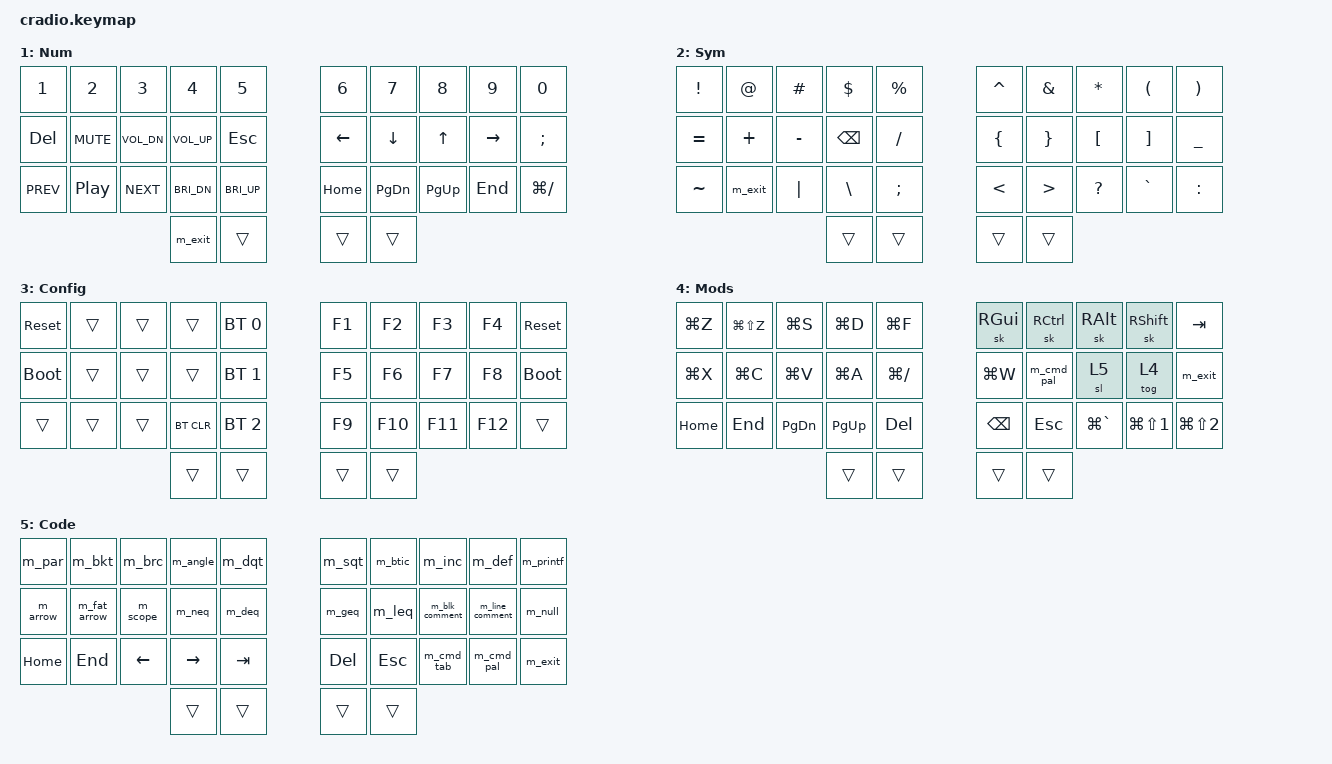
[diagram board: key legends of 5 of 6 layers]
// Copyright (c) 2022 The ZMK Contributors
// SPDX-License-Identifier: MIT

// ─── C / General Coding Optimised Keymap ─────────────────────────────────────
//
// Key ideas:
//  • Bracket-pair macros — type the pair, cursor lands INSIDE: () {} [] "" '' ``
//    reached via combos (UI OP IO) and Code layer — NOT on Sym row 0
//  • EXIT→→ macro           — double RIGHT, hops past closing bracket/quote
//                             Num left thumb (30), Sym row2 (21), Code/Mod layers
//  • Key Repeat (pos 30)   — repeats last key; ideal for arrows, chars, etc.
//  • Standard symbol row    — Sym TOP ROW mirrors shift+1–0 exactly:
//                             !  @  #  $  %  ^  &  *  (  )
//  • Complete symbol set    — every symbol reachable on Sym without shift:
//                             Row 1: =  +  -  BSPC  /  {  }  [  ]  _
//                             Row 2: ~  EXIT  |  \  ;  <  >  ?  `  :
//  • C-specific macros      — -> => :: /* */ // #include <> #define printf("") NULL
//  • Comparison macros      — != == >= <=  on Code layer + combos
//  • Cmd+Tab macro          — app switcher on Sym right outer thumb + combo RT
//  • Combos on natural rolls — SD=Esc  JK=Tab  JKL=Mods  AS=Code  DF=:
//                             QW=⌘Z  WE=⌘⇧Z  ZX=⌘S  RT=⌘Tab  ,.=;
//                             UI=()  IO={}  OP=[]  HJ===  NM=!=  XC=""
//                             VB=/**/
//  • All shortcuts use Cmd (⌘) not Ctrl — macOS native
//
// Symbols layer at a glance:
//   Row 0  !  @  #  $  %    ^  &  *  (  )    ← standard shift+number row
//   Row 1  =  +  -  BSPC /  {  }  [  ]  _   ← arithmetic + brackets + BSPC
//   Row 2  ~  EXIT |  \  ;  <  >  ?  `  :   ← bitwise / misc + EXIT→→
//   Thumb  —  [held]         —     ⌘Tab
//
// Layer index:
//   0  Base     (QWERTY + HRM)
//   1  Num      (right thumb hold)
//   2  Sym      (left thumb hold)
//   3  Config   (tri-layer: 1 + 2)
//   4  Mods     (JKL combo toggle)
//   5  Code     (sticky / one-shot, access via AS combo or Mods layer)

#include <behaviors.dtsi>
#include <dt-bindings/zmk/keys.h>
#include <dt-bindings/zmk/bt.h>

// ─── Home row mod helpers ─────────────────────────────────────────────────────
// Left:  A=LSHFT  S=LALT  D=LCTRL  F=LGUI
// Right: J=RGUI   K=RCTRL L=RALT   '=RSHFT
//
// FIX: Both HRML(k1) and HRMR(k4) now use &ht so the outer home-row keys
//      (A=LSHFT and '=RSHFT) actually fire their hold behaviour.
#define HRML(k1,k2,k3,k4) &ht LSHFT k1  &ht LALT k2  &ht LCTRL k3  &ht LGUI k4
#define HRMR(k1,k2,k3,k4) &ht RGUI k1   &ht RCTRL k2 &ht RALT k3   &ht RSHFT k4

// ─── Hold-tap tuning ──────────────────────────────────────────────────────────
&lt {
    flavor = "tap-preferred";
    tapping-term-ms = <250>;
    quick-tap-ms = <180>;
    require-prior-idle-ms = <100>;
};

&sk {
    release-after-ms = <2000>;
    quick-release;
};

&sl {
    release-after-ms = <2000>;
};

// ─── Root node ────────────────────────────────────────────────────────────────
/ {

    // ── Behaviors ─────────────────────────────────────────────────────────────

    behaviors {

        ht: hold_tap {
            compatible = "zmk,behavior-hold-tap";
            #binding-cells = <2>;
            flavor = "tap-preferred";
            tapping-term-ms = <280>;
            quick-tap-ms = <180>;
            require-prior-idle-ms = <125>;
            bindings = <&kp>, <&kp>;
        };

        ccaps_word: caps_word {
            compatible = "zmk,behavior-caps-word";
            #binding-cells = <0>;
            continue-list = <UNDERSCORE MINUS BACKSPACE>;
        };

        rpt: key_repeat {
            compatible = "zmk,behavior-key-repeat";
            #binding-cells = <0>;
            usage-pages = <HID_USAGE_KEY HID_USAGE_CONSUMER>;
        };

    };

    // ── Macros ────────────────────────────────────────────────────────────────
    //
    // Bracket-pair macros type open+close then move LEFT → cursor is inside.
    // They live on combos (Base layer) and on Code layer (L5).
    // The Sym layer (L2) exposes raw individual symbols only.
    //
    // tap-ms / wait-ms = 15 ms keeps HID events ordered over BLE.

    macros {

        // ── Bracket pairs (cursor inside after) ───────────────────────────────

        m_par: macro_parens {
            compatible = "zmk,behavior-macro";
            #binding-cells = <0>;
            wait-ms = <15>; tap-ms = <15>;
            bindings = <&kp LPAR &kp RPAR &kp LEFT>;
        };

        m_bkt: macro_brackets {
            compatible = "zmk,behavior-macro";
            #binding-cells = <0>;
            wait-ms = <15>; tap-ms = <15>;
            bindings = <&kp LBKT &kp RBKT &kp LEFT>;
        };

        m_brc: macro_braces {
            compatible = "zmk,behavior-macro";
            #binding-cells = <0>;
            wait-ms = <15>; tap-ms = <15>;
            bindings = <&kp LBRC &kp RBRC &kp LEFT>;
        };

        m_dqt: macro_double_quote {
            compatible = "zmk,behavior-macro";
            #binding-cells = <0>;
            wait-ms = <15>; tap-ms = <15>;
            bindings = <&kp DQT &kp DQT &kp LEFT>;
        };

        m_sqt: macro_single_quote {
            compatible = "zmk,behavior-macro";
            #binding-cells = <0>;
            wait-ms = <15>; tap-ms = <15>;
            bindings = <&kp SQT &kp SQT &kp LEFT>;
        };

        m_btic: macro_backtick {
            compatible = "zmk,behavior-macro";
            #binding-cells = <0>;
            wait-ms = <15>; tap-ms = <15>;
            bindings = <&kp GRAVE &kp GRAVE &kp LEFT>;
        };

        m_angle: macro_angle_brackets {
            compatible = "zmk,behavior-macro";
            #binding-cells = <0>;
            wait-ms = <15>; tap-ms = <15>;
            bindings = <&kp LT &kp GT &kp LEFT>;
        };

        // ── Exit bracket ───────────────────────────────────────────────────────
        // Two RIGHT presses: covers manually typed AND editor-autoclosed brackets.

        m_exit: macro_exit_bracket {
            compatible = "zmk,behavior-macro";
            #binding-cells = <0>;
            wait-ms = <15>; tap-ms = <15>;
            bindings = <&kp RIGHT &kp RIGHT>;
        };

        // ── C / multi-language snippets ────────────────────────────────────────

        m_arrow: macro_arrow {          // ->
            compatible = "zmk,behavior-macro";
            #binding-cells = <0>;
            wait-ms = <15>; tap-ms = <15>;
            bindings = <&kp MINUS &kp GT>;
        };

        m_fat_arrow: macro_fat_arrow {  // =>
            compatible = "zmk,behavior-macro";
            #binding-cells = <0>;
            wait-ms = <15>; tap-ms = <15>;
            bindings = <&kp EQUAL &kp GT>;
        };

        m_scope: macro_scope {          // ::
            compatible = "zmk,behavior-macro";
            #binding-cells = <0>;
            wait-ms = <15>; tap-ms = <15>;
            bindings = <&kp COLON &kp COLON>;
        };

        m_blk_comment: macro_block_comment {   // /*  */  cursor between spaces
            compatible = "zmk,behavior-macro";
            #binding-cells = <0>;
            wait-ms = <15>; tap-ms = <15>;
            bindings =
                <&kp FSLH &kp ASTRK &kp SPACE &kp SPACE &kp ASTRK &kp FSLH>,
                <&kp LEFT &kp LEFT &kp LEFT>;
        };

        m_line_comment: macro_line_comment {   // // (with trailing space)
            compatible = "zmk,behavior-macro";
            #binding-cells = <0>;
            wait-ms = <15>; tap-ms = <15>;
            bindings = <&kp FSLH &kp FSLH &kp SPACE>;
        };

        m_neq: macro_not_equal {        // !=
            compatible = "zmk,behavior-macro";
            #binding-cells = <0>;
            wait-ms = <15>; tap-ms = <15>;
            bindings = <&kp EXCL &kp EQUAL>;
        };

        m_deq: macro_double_equal {     // ==
            compatible = "zmk,behavior-macro";
            #binding-cells = <0>;
            wait-ms = <15>; tap-ms = <15>;
            bindings = <&kp EQUAL &kp EQUAL>;
        };

        m_geq: macro_geq {              // >=
            compatible = "zmk,behavior-macro";
            #binding-cells = <0>;
            wait-ms = <15>; tap-ms = <15>;
            bindings = <&kp GT &kp EQUAL>;
        };

        m_leq: macro_leq {              // <=
            compatible = "zmk,behavior-macro";
            #binding-cells = <0>;
            wait-ms = <15>; tap-ms = <15>;
            bindings = <&kp LT &kp EQUAL>;
        };

        // FIX: m_inc — replaced fragile &macro_press/tap/release LSHFT+N3 pattern
        //      with direct &kp HASH (defined in zmk/keys.h). Same fix for m_def.
        m_inc: macro_include {          // #include <|>
            compatible = "zmk,behavior-macro";
            #binding-cells = <0>;
            wait-ms = <15>; tap-ms = <15>;
            bindings =
                <&kp HASH>,
                <&kp I &kp N &kp C &kp L &kp U &kp D &kp E &kp SPACE>,
                <&kp LT &kp GT &kp LEFT>;
        };

        m_def: macro_define {           // #define (trailing space)
            compatible = "zmk,behavior-macro";
            #binding-cells = <0>;
            wait-ms = <15>; tap-ms = <15>;
            bindings =
                <&kp HASH>,
                <&kp D &kp E &kp F &kp I &kp N &kp E &kp SPACE>;
        };

        m_printf: macro_printf {        // printf("|")
            compatible = "zmk,behavior-macro";
            #binding-cells = <0>;
            wait-ms = <15>; tap-ms = <15>;
            bindings =
                <&kp P &kp R &kp I &kp N &kp T &kp F>,
                <&kp LPAR &kp DQT &kp DQT &kp RPAR &kp SEMI>,
                <&kp LEFT &kp LEFT &kp LEFT>;
        };

        // FIX: m_null — replaced broken &macro_press/tap/release pattern with
        //      individual &kp LS(...) calls, which correctly hold shift per key.
        m_null: macro_null {            // NULL
            compatible = "zmk,behavior-macro";
            #binding-cells = <0>;
            wait-ms = <15>; tap-ms = <15>;
            bindings = <&kp LS(N) &kp LS(U) &kp LS(L) &kp LS(L)>;
        };

        // ── OS macros ─────────────────────────────────────────────────────────

        m_cmd_tab: macro_cmd_tab {      // ⌘Tab — app switcher
            compatible = "zmk,behavior-macro";
            #binding-cells = <0>;
            wait-ms = <15>; tap-ms = <15>;
            bindings = <&kp LG(TAB)>;
        };

        m_cmd_pal: macro_cmd_palette {  // ⌘⇧P — command palette
            compatible = "zmk,behavior-macro";
            #binding-cells = <0>;
            wait-ms = <15>; tap-ms = <15>;
            bindings = <&kp LG(LS(P))>;
        };
    };

    // ── Conditional layers ────────────────────────────────────────────────────
    conditional_layers {
        compatible = "zmk,conditional-layers";
        tri_layer {
            if-layers = <1 2>;
            then-layer = <3>;
        };
    };

    // ── Combos ────────────────────────────────────────────────────────────────
    //
    // All timeouts ≤ 30 ms.
    //
    // Position map:
    //  0  1  2  3  4    5  6  7  8  9
    // 10 11 12 13 14   15 16 17 18 19
    // 20 21 22 23 24   25 26 27 28 29
    //          30 31   32 33

    combos {
        compatible = "zmk,combos";

        // ── Utility ───────────────────────────────────────────────────────────

        combo_esc {           // SD → Escape
            timeout-ms = <30>;
            key-positions = <12 13>;
            bindings = <&kp ESC>;
        };

        combo_tab {           // JK → Tab
            timeout-ms = <30>;
            key-positions = <16 17>;
            bindings = <&kp TAB>;
        };

        // FIX: comment updated — this is JKL (positions 16 17 18), not GH
        combo_mod {           // JKL → Toggle Mods layer (L4)
            timeout-ms = <30>;
            key-positions = <16 17 18>;
            bindings = <&tog 4>;
        };

        // FIX: comment updated — this is AS (positions 10 11), not QA
        combo_code {          // AS → One-shot Code layer (L5)
            timeout-ms = <30>;
            key-positions = <10 11>;
            bindings = <&sl 5>;
        };

        combo_colon {         // DF → Colon
            timeout-ms = <30>;
            key-positions = <13 14>;
            bindings = <&kp COLON>;
        };

        combo_semi {          // ,. → Semicolon
            timeout-ms = <30>;
            key-positions = <27 28>;
            bindings = <&kp SEMI>;
        };

        combo_caps {          // CV → Caps Word
            timeout-ms = <30>;
            key-positions = <22 23>;
            bindings = <&ccaps_word>;
        };

        // ── Editing (left hand top / bottom rows) ─────────────────────────────

        combo_undo {          // QW → ⌘Z
            timeout-ms = <30>;
            key-positions = <0 1>;
            bindings = <&kp LG(Z)>;
        };

        combo_redo {          // WE → ⌘⇧Z
            timeout-ms = <30>;
            key-positions = <1 2>;
            bindings = <&kp LG(LS(Z))>;
        };

        combo_save {          // ZX → ⌘S
            timeout-ms = <30>;
            key-positions = <20 21>;
            bindings = <&kp LG(S)>;
        };

        combo_cmd_tab {       // RT → ⌘Tab
            timeout-ms = <30>;
            key-positions = <3 4>;
            bindings = <&m_cmd_tab>;
        };

        // ── Bracket pair macros (right hand top row) ──────────────────────────

        combo_parens {        // UI → () pair
            timeout-ms = <30>;
            key-positions = <6 7>;
            bindings = <&m_par>;
        };

        combo_braces {        // IO → {} pair
            timeout-ms = <30>;
            key-positions = <7 8>;
            bindings = <&m_brc>;
        };

        combo_brackets {      // OP → [] pair
            timeout-ms = <30>;
            key-positions = <8 9>;
            bindings = <&m_bkt>;
        };

        combo_dquotes {       // XC → "" pair
            timeout-ms = <30>;
            key-positions = <21 22>;
            bindings = <&m_dqt>;
        };

        // ── Operator combos ───────────────────────────────────────────────────

        combo_deq {           // HJ → ==
            timeout-ms = <30>;
            key-positions = <15 16>;
            bindings = <&m_deq>;
        };

        combo_neq {           // NM → !=
            timeout-ms = <30>;
            key-positions = <25 26>;
            bindings = <&m_neq>;
        };

        // ── Comment combos ────────────────────────────────────────────────────

        combo_blk_comment {   // VB → /* */
            timeout-ms = <30>;
            key-positions = <23 24>;
            bindings = <&m_blk_comment>;
        };
    };

    // ── Keymap ────────────────────────────────────────────────────────────────

    keymap {
        compatible = "zmk,keymap";

        // ┌─────────────────────────────────────────────────────────────────────┐
        // │  Layer 0 — Base  (QWERTY + Home Row Mods)                           │
        // └─────────────────────────────────────────────────────────────────────┘
        //
        // HRM left : A=LSHFT  S=LALT  D=LCTRL  F=LGUI
        // HRM right: J=RGUI   K=RCTRL L=RALT   '=RSHFT
        // Left thumb : outer=Key Repeat  inner hold=Sym(2) tap=Enter
        // Right thumb: inner hold=Num(1) tap=Space  outer=BSPC

        default_layer {
            display-name = "Base";
            bindings = <
        //╭──────────┬──────────┬──────────┬──────────┬──────────╮   ╭──────────┬──────────┬──────────┬──────────┬──────────╮
        //│  Q       │  W       │  E       │  R       │  T       │   │  Y       │  U       │  I       │  O       │  P       │
        //│[QW=⌘Z]   │[WE=⌘⇧Z]  │          │[RT=⌘Tab] │[RT=⌘Tab] │   │          │[UI=()]   │[IO={}]   │[OP=[]]   │          │
            &kp Q      &kp W      &kp E      &kp R      &kp T          &kp Y      &kp U      &kp I      &kp O      &kp P
        //├──────────┼──────────┼──────────┼──────────┼──────────┤   ├──────────┼──────────┼──────────┼──────────┼──────────┤
        //│  A       │  S       │  D       │  F       │  G       │   │  H       │  J       │  K       │  L       │  '       │
        //│ LSHFT    │ LALT     │ LCTRL    │ LGUI     │          │   │          │ RGUI     │ RCTRL    │ RALT     │ RSHFT    │
        //│[AS=Code] │[AS=Code] │[SD=Esc]  │[DF=:]    │          │   │[HJ===]   │[JK=Tab]  │[JKL=Mod] │          │          │
            HRML(A,        S,         D,         F)     &kp G          &kp H      HRMR(J,        K,         L,        SQT)
        //├──────────┼──────────┼──────────┼──────────┼──────────┤   ├──────────┼──────────┼──────────┼──────────┼──────────┤
        //│  Z       │  X       │  C       │  V       │  B       │   │  N       │  M       │  ,       │  .       │  /       │
        //│[ZX=⌘S]   │[XC=""]   │[CV=Caps] │[VB=/**/] │          │   │[NM=!=]   │          │[,.=;]    │[,.=;]    │          │
            &kp Z      &kp X      &kp C      &kp V      &kp B          &kp N      &kp M      &kp COMMA  &kp DOT    &kp FSLH
        //╰──────────┴──────────┴──────────┼──────────┼──────────┤   ├──────────┼──────────┼──────────┴──────────┴──────────╯
        //                                 │ KEY RPT  │ ENT / L2 │   │ SPC / L1 │  BSPC    │
        //                                 │          │          │   │          │          │
                                             &rpt       &lt 2 ENTER   &lt 1 SPACE &kp BSPC
        //                                 ╰──────────┴──────────╯   ╰──────────┴──────────╯
            >;
        };

        // ┌─────────────────────────────────────────────────────────────────────┐
        // │  Layer 1 — Num  (right thumb hold)                                  │
        // │                                                                     │
        // │  Row 0 : 1 – 0                                                      │
        // │  Row 1 : DEL  media  ←  ↓  ↑  →  ;                                  │
        // │  Row 2 : media + brightness + navigation                            │
        // └─────────────────────────────────────────────────────────────────────┘
        right_layer {
            display-name = "Num";
            bindings = <
        //╭──────────┬──────────┬──────────┬──────────┬──────────╮   ╭──────────┬──────────┬──────────┬──────────┬──────────╮
        //│  1       │  2       │  3       │  4       │  5       │   │  6       │  7       │  8       │  9       │  0       │
            &kp N1     &kp N2     &kp N3     &kp N4     &kp N5         &kp N6     &kp N7     &kp N8     &kp N9     &kp N0
        //├──────────┼──────────┼──────────┼──────────┼──────────┤   ├──────────┼──────────┼──────────┼──────────┼──────────┤
        //│ DEL      │ MUTE     │ VOL-     │ VOL+     │ ESC      │   │  ←       │  ↓       │  ↑       │  →       │  ;       │
            &kp DEL    &kp C_MUTE &kp C_VOL_DN &kp C_VOL_UP &kp ESC  &kp LEFT   &kp DOWN   &kp UP     &kp RIGHT  &kp SEMI
        //├──────────┼──────────┼──────────┼──────────┼──────────┤   ├──────────┼──────────┼──────────┼──────────┼──────────┤
        //│ PREV     │ PAUSE    │ NEXT     │ BRI-     │ BRI+     │   │ HOME     │ PG_DN    │ PG_UP    │ END      │ ⌘/ Cmt   │
            &kp C_PREV &kp C_PP &kp C_NEXT &kp C_BRI_DN &kp C_BRI_UP &kp HOME &kp PG_DN  &kp PG_UP  &kp END   &kp LG(FSLH)
        //╰──────────┴──────────┴──────────┼──────────┼──────────┤   ├──────────┼──────────┼──────────┴──────────┴──────────╯
        //                                 │ EXIT→→   │          │   │ [held]   │  BSPC    │
                                             &m_exit    &trans         &trans     &trans
        //                                 ╰──────────┴──────────╯   ╰──────────┴──────────╯
            >;
        };

        // ┌─────────────────────────────────────────────────────────────────────┐
        // │  Layer 2 — Sym  (left thumb hold)                                   │
        // │                                                                     │
        // │  Row 0 — standard shift+number row (exactly as on a keyboard):      │
        // │    !   @   #   $   %      ^   &   *   (   )                         │
        // │                                                                     │
        // │  Row 1 — arithmetic + brackets + BSPC (replaces dup *):             │
        // │    =   +   -  BSPC /      {   }   [   ]   _                         │
        // │                                                                     │
        // │  Row 2 — bitwise / punctuation / EXIT→→ (replaces dup ^):           │
        // │    ~  EXIT  |   \   ;      <   >   ?   `   :                        │
        // │                                                                     │
        // │  Thumbs: [held] (pos 31)  |  ⌘Tab (pos 33)                          │
        // └─────────────────────────────────────────────────────────────────────┘
        left_layer {
            display-name = "Sym";
            bindings = <
        //╭──────────┬──────────┬──────────┬──────────┬──────────╮   ╭──────────┬──────────┬──────────┬──────────┬──────────╮
        //│  !       │  @       │  #       │  $       │  %       │   │  ^       │  &       │  *       │  (       │  )       │
            &kp EXCL   &kp AT     &kp HASH   &kp DLLR   &kp PRCNT      &kp CARET  &kp AMPS   &kp ASTRK  &kp LPAR   &kp RPAR
        //├──────────┼──────────┼──────────┼──────────┼──────────┤   ├──────────┼──────────┼──────────┼──────────┼──────────┤
        //│  =       │  +       │  -       │  BSPC    │  /       │   │  {       │  }       │  [       │  ]       │  _       │
            &kp EQUAL  &kp PLUS   &kp MINUS  &kp BSPC   &kp FSLH       &kp LBRC   &kp RBRC   &kp LBKT   &kp RBKT   &kp UNDER
        //├──────────┼──────────┼──────────┼──────────┼──────────┤   ├──────────┼──────────┼──────────┼──────────┼──────────┤
        //│  ~       │ EXIT→→   │  |       │  \       │  ;       │   │  <       │  >       │  ?       │  `       │  :       │
            &kp TILDE  &m_exit    &kp PIPE   &kp BSLH   &kp SEMI       &kp LT     &kp GT     &kp QMARK  &kp GRAVE  &kp COLON
        //╰──────────┴──────────┴──────────┼──────────┼──────────┤   ├──────────┼──────────┼──────────┴──────────┴──────────╯
        //                                 │          │ [held]   │   │          │  ⌘Tab    │
                                             &trans     &trans         &trans    &trans 
        //                                 ╰──────────┴──────────╯   ╰──────────┴──────────╯
            >;
        };

        // ┌─────────────────────────────────────────────────────────────────────┐
        // │  Layer 3 — Config  (both thumbs held = tri-layer)                    │
        // └─────────────────────────────────────────────────────────────────────┘
        tri_layer {
            display-name = "Config";
            bindings = <
        //╭──────────┬──────────┬──────────┬──────────┬──────────╮   ╭──────────┬──────────┬──────────┬──────────┬──────────╮
        //│ SYS_RST  │          │          │          │  BT 0    │   │  F1      │  F2      │  F3      │  F4      │ SYS_RST  │
            &sys_reset &trans     &trans     &trans     &bt BT_SEL 0   &kp F1     &kp F2     &kp F3     &kp F4     &sys_reset
        //├──────────┼──────────┼──────────┼──────────┼──────────┤   ├──────────┼──────────┼──────────┼──────────┼──────────┤
        //│ BOOT     │          │          │          │  BT 1    │   │  F5      │  F6      │  F7      │  F8      │ BOOT     │
            &bootloader &trans    &trans     &trans     &bt BT_SEL 1   &kp F5     &kp F6     &kp F7     &kp F8     &bootloader
        //├──────────┼──────────┼──────────┼──────────┼──────────┤   ├──────────┼──────────┼──────────┼──────────┼──────────┤
        //│          │          │          │  BT CLR  │  BT 2    │   │  F9      │  F10     │  F11     │  F12     │          │
            &trans     &trans     &trans     &bt BT_CLR &bt BT_SEL 2   &kp F9     &kp F10    &kp F11    &kp F12    &trans
        //╰──────────┴──────────┴──────────┼──────────┼──────────┤   ├──────────┼──────────┼──────────┴──────────┴──────────╯
                                             &trans     &trans         &trans     &trans
        //                                 ╰──────────┴──────────╯   ╰──────────┴──────────╯
            >;
        };

        // ┌─────────────────────────────────────────────────────────────────────┐
        // │  Layer 4 — Mods  (JKL combo toggle)                                 │
        // │                                                                     │
        // │  FIX: mod_layer is now defined FIRST so ZMK assigns it index 4,     │
        // │  matching all combo bindings (&tog 4) and self-references (&tog 4)  │
        // │  inside the layer. code_layer follows at index 5, matching &sl 5.   │
        // └─────────────────────────────────────────────────────────────────────┘

        mod_layer {
            display-name = "Mods";
            bindings = <
        //╭──────────┬──────────┬──────────┬──────────┬──────────╮   ╭──────────┬──────────┬──────────┬──────────┬──────────╮
        //│ UNDO     │ REDO     │ SAVE     │ DUP      │ FIND     │   │ SK RGUI  │ SK RCTRL │ SK RALT  │ SK RSHFT │  TAB     │
            &kp LG(Z)  &kp LG(LS(Z)) &kp LG(S) &kp LG(D) &kp LG(F)      &sk RGUI   &sk RCTRL  &sk RALT   &sk RSHFT  &kp TAB
        //├──────────┼──────────┼──────────┼──────────┼──────────┤   ├──────────┼──────────┼──────────┼──────────┼──────────┤
        //│ CUT      │ COPY     │ PASTE    │ SEL ALL  │ CMT      │   │ CLOSE    │ PAL      │ CODE     │ MODS off │ EXIT→→   │
            &kp LG(X)  &kp LG(C)  &kp LG(V)  &kp LG(A)  &kp LG(FSLH)  &kp LG(W) &m_cmd_pal &sl 5    &tog 4    &m_exit
        //├──────────┼──────────┼──────────┼──────────┼──────────┤   ├──────────┼──────────┼──────────┼──────────┼──────────┤
        //│ HOME     │ END      │ PG_DN    │ PG_UP    │ DEL      │   │ BSPC     │ ESC      │ ⌘`Win    │ ⌘⇧1 Scrn │ ⌘⇧2 Rec  │
            &kp HOME   &kp END   &kp PG_DN  &kp PG_UP  &kp DEL     &kp BSPC   &kp ESC  &kp LG(GRAVE) &kp LG(LS(N1)) &kp LG(LS(N2))
        //╰──────────┴──────────┴──────────┼──────────┼──────────┤   ├──────────┼──────────┼──────────┴──────────┴──────────╯
                                             &trans     &trans        &trans     &trans
            >;
        };

        // ┌─────────────────────────────────────────────────────────────────────┐
        // │  Layer 5 — Code  (sticky / one-shot, via AS combo or Mods layer)    │
        // │  Bracket pairs, snippets, operators, navigation                     │
        // └─────────────────────────────────────────────────────────────────────┘
        code_layer {
            display-name = "Code";
            bindings = <
        //╭──────────┬──────────┬──────────┬──────────┬──────────╮   ╭──────────┬──────────┬──────────┬──────────┬──────────╮
        //│  () pair │  [] pair │  {} pair │  <> pair │  "" pair │   │  '' pair │  `` pair │ #include │ #define  │ printf() │
            &m_par     &m_bkt     &m_brc     &m_angle   &m_dqt         &m_sqt     &m_btic    &m_inc     &m_def     &m_printf
        //├──────────┼──────────┼──────────┼──────────┼──────────┤   ├──────────┼──────────┼──────────┼──────────┼──────────┤
        //│  ->      │  =>      │  ::      │  !=      │  ==      │   │  >=      │  <=      │ /* */    │ //       │ NULL     │
            &m_arrow   &m_fat_arrow &m_scope  &m_neq     &m_deq        &m_geq     &m_leq     &m_blk_comment &m_line_comment &m_null
        //├──────────┼──────────┼──────────┼──────────┼──────────┤   ├──────────┼──────────┼──────────┼──────────┼──────────┤
        //│  HOME    │  END     │  LEFT    │  RIGHT   │  TAB     │   │  DEL     │  ESC     │  ⌘Tab    │  ⌘⇧P     │  EXIT→→  │
            &kp HOME   &kp END    &kp LEFT   &kp RIGHT  &kp TAB       &kp DEL    &kp ESC    &m_cmd_tab &m_cmd_pal &m_exit
        //╰──────────┴──────────┴──────────┼──────────┼──────────┤   ├──────────┼──────────┼──────────┴──────────┴──────────╯
                                             &trans     &trans        &trans     &trans
            >;
        };
    };
};
